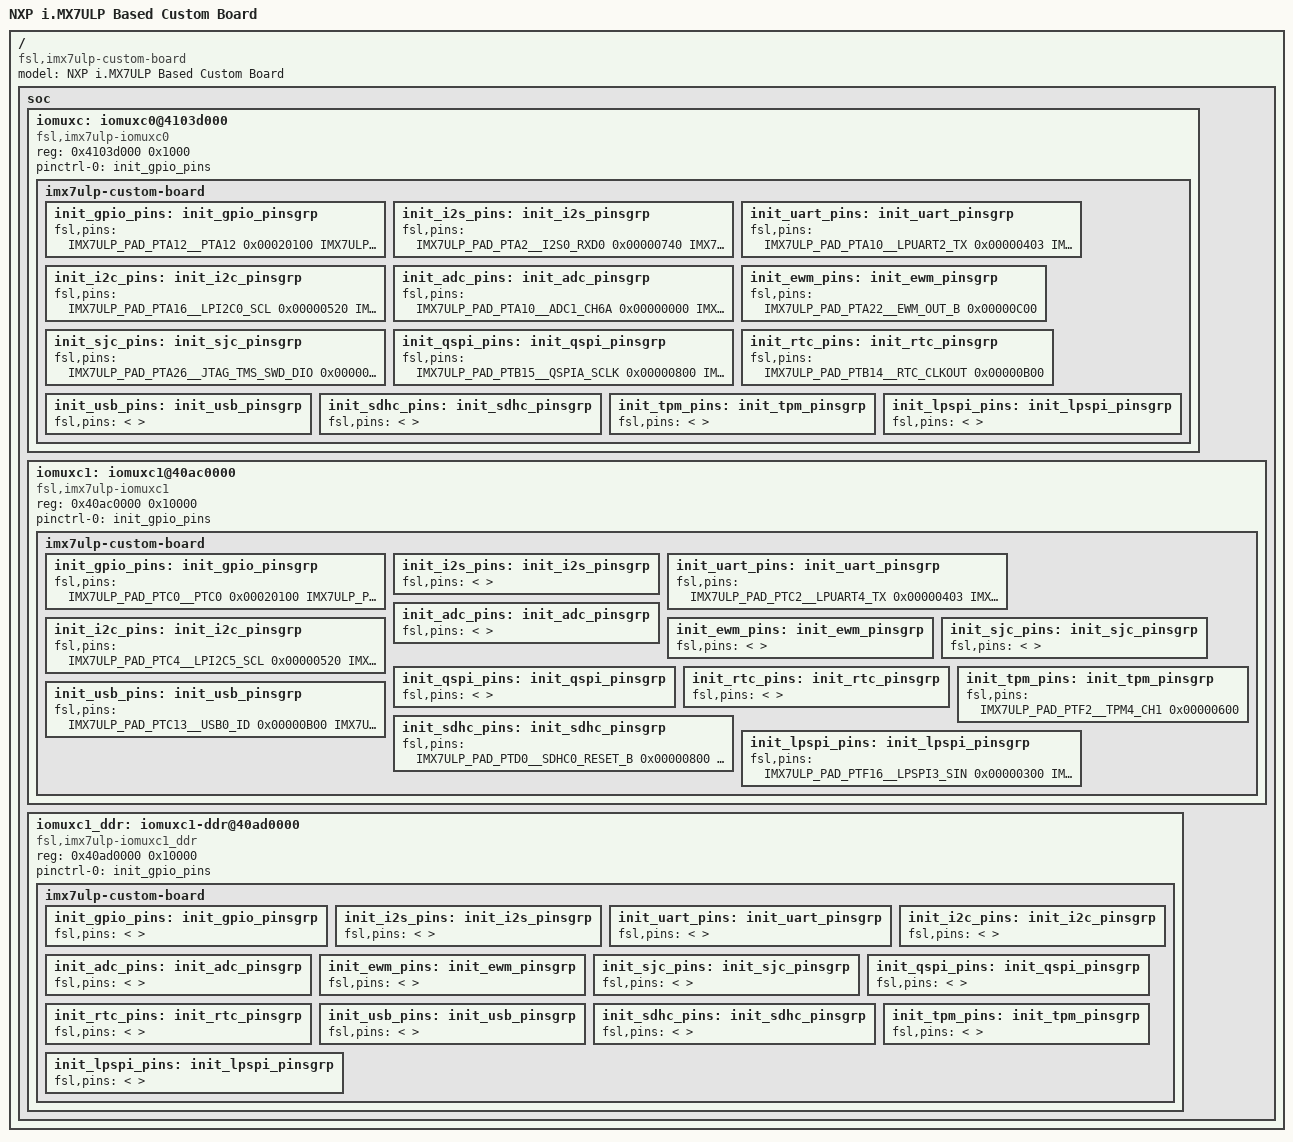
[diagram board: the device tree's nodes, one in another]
/***********************************************************************************************************************
 * This file was generated by the MCUXpresso Config Tools. Any manual edits made to this file
 * will be overwritten if the respective MCUXpresso Config Tools is used to update this file.
 **********************************************************************************************************************/

/*
 * TEXT BELOW IS USED AS SETTING FOR TOOLS *************************************
!!GlobalInfo
product: Pins v7.0
processor: MCIMX7U5xxxxx
package_id: MCIMX7U5CVP05
mcu_data: ksdk2_0
processor_version: 7.0.1
board: MCIMX7ULP-EVK-REV-B
 * BE CAREFUL MODIFYING THIS COMMENT - IT IS YAML SETTINGS FOR TOOLS ***********
 */


/dts-v1/;

#include "skeleton.dtsi"
#include "imx7ulp-pinfunc.h"

/ {
    model = "NXP i.MX7ULP Based Custom Board";
    compatible = "fsl,imx7ulp-custom-board", "fsl,imx7ulp";

    soc {
        #address-cells = <1>;
        #size-cells = <1>;

        iomuxc: iomuxc0@4103d000 {
            compatible = "fsl,imx7ulp-iomuxc0";
            reg = <0x4103d000 0x1000>;
        };
        iomuxc1: iomuxc1@40ac0000 {
            compatible = "fsl,imx7ulp-iomuxc1";
            reg = <0x40ac0000 0x10000>;
        };

        iomuxc1_ddr: iomuxc1-ddr@40ad0000 {
            compatible = "fsl,imx7ulp-iomuxc1_ddr";
            reg = <0x40ad0000 0x10000>;
        };
    };
};

&iomuxc {
    pinctrl-names = "default_iomuxc0";
    pinctrl-0 = <&init_gpio_pins>;


    imx7ulp-custom-board {
        init_gpio_pins: init_gpio_pinsgrp {                /*!< Function assigned for the core: Cortex-M4[cm4] */
/*
 * TEXT BELOW IS USED AS SETTING FOR TOOLS *************************************
init_gpio_pins:
- options: {callFromInitBoot: 'false', coreID: cm4}
- pin_list:
  - {pin_num: AG16, peripheral: PTA, signal: 'port, 12', pin_signal: PTA12, direction: OUTPUT, OBE: OBE_1_Enabled}
  - {pin_num: AF16, peripheral: PTA, signal: 'port, 13', pin_signal: PTA13, direction: INPUT, IBE: IBE_1_Enabled}
  - {pin_num: AF17, peripheral: PTA, signal: 'port, 14', pin_signal: PTA14, direction: OUTPUT, OBE: OBE_1_Enabled}
  - {pin_num: AF18, peripheral: PTA, signal: 'port, 15', pin_signal: PTA15, direction: OUTPUT, OBE: OBE_1_Enabled}
  - {pin_num: AB20, peripheral: PTA, signal: 'port, 21', pin_signal: PTA21, direction: OUTPUT, OBE: OBE_1_Enabled}
  - {pin_num: AD20, peripheral: PTA, signal: 'port, 23', pin_signal: PTA23, direction: INPUT, IBE: IBE_1_Enabled}
  - {pin_num: AF20, peripheral: PTA, signal: 'port, 24', pin_signal: PTA24, direction: OUTPUT, OBE: OBE_1_Enabled}
  - {pin_num: AG20, peripheral: PTA, signal: 'port, 25', pin_signal: PTA25, direction: OUTPUT, OBE: OBE_1_Enabled}
  - {pin_num: AF14, peripheral: PTA, signal: 'port, 3', pin_signal: PTA3, direction: OUTPUT, OBE: OBE_1_Enabled}
  - {pin_num: AF24, peripheral: PTA, signal: 'port, 31', pin_signal: PTA31, direction: INPUT, IBE: IBE_1_Enabled}
  - {pin_num: AF5, peripheral: PTB, signal: 'port, 6', pin_signal: PTB6, direction: OUTPUT, OBE: OBE_1_Enabled}
  - {pin_num: AF6, peripheral: PTB, signal: 'port, 7', pin_signal: PTB7, direction: INPUT, IBE: IBE_1_Enabled}
  - {pin_num: AD7, peripheral: PTB, signal: 'port, 9', pin_signal: PTB9, direction: INPUT, IBE: IBE_1_Enabled}
  - {pin_num: AB7, peripheral: PTB, signal: 'port, 11', pin_signal: PTB11, direction: INPUT, IBE: IBE_1_Enabled}
  - {pin_num: D18, peripheral: PTC, signal: 'port, 0', pin_signal: PTC0, direction: OUTPUT, OBE: OBE_1_Enabled}
  - {pin_num: B15, peripheral: PTC, signal: 'port, 10', pin_signal: PTC10, direction: INPUT, IBE: IBE_1_Enabled, PE: PE_1_pull_enabled, PS: PS_1_pull_up}
  - {pin_num: B14, peripheral: PTC, signal: 'port, 11', pin_signal: PTC11, direction: INPUT, IBE: IBE_1_Enabled}
  - {pin_num: A14, peripheral: PTC, signal: 'port, 12', pin_signal: PTC12, direction: INPUT, IBE: IBE_1_Enabled}
  - {pin_num: E13, peripheral: PTC, signal: 'port, 14', pin_signal: PTC14, direction: OUTPUT, OBE: OBE_1_Enabled}
  - {pin_num: F13, peripheral: PTC, signal: 'port, 15', pin_signal: PTC15, direction: OUTPUT, OBE: OBE_1_Enabled}
  - {pin_num: G12, peripheral: PTC, signal: 'port, 17', pin_signal: PTC17, direction: OUTPUT, OBE: OBE_1_Enabled}
  - {pin_num: F12, peripheral: PTC, signal: 'port, 18', pin_signal: PTC18, direction: INPUT, IBE: IBE_1_Enabled, PE: PE_1_pull_enabled, PS: PS_1_pull_up}
  - {pin_num: E12, peripheral: PTC, signal: 'port, 19', pin_signal: PTC19, direction: OUTPUT, OBE: OBE_1_Enabled, PE: PE_1_pull_enabled, PS: PS_1_pull_up}
  - {pin_num: B8, peripheral: PTE, signal: 'port, 12', pin_signal: PTE12, direction: OUTPUT, OBE: OBE_1_Enabled}
  - {pin_num: D2, peripheral: PTF, signal: 'port, 0', pin_signal: PTF0, direction: INPUT, IBE: IBE_1_Enabled}
  - {pin_num: B2, peripheral: PTF, signal: 'port, 1', pin_signal: PTF1, direction: OUTPUT, OBE: OBE_1_Enabled}
  - {pin_num: G5, peripheral: PTF, signal: 'port, 10', pin_signal: PTF10, direction: OUTPUT, OBE: OBE_1_Enabled}
  - {pin_num: G6, peripheral: PTF, signal: 'port, 11', pin_signal: PTF11, direction: OUTPUT, OBE: OBE_1_Enabled}
 * BE CAREFUL MODIFYING THIS COMMENT - IT IS YAML SETTINGS FOR TOOLS ***********
 */
            fsl,pins = <
                IMX7ULP_PAD_PTA12__PTA12                   0x00020100
                IMX7ULP_PAD_PTA13__PTA13                   0x00010100
                IMX7ULP_PAD_PTA14__PTA14                   0x00020100
                IMX7ULP_PAD_PTA15__PTA15                   0x00020100
                IMX7ULP_PAD_PTA21__PTA21                   0x00020100
                IMX7ULP_PAD_PTA23__PTA23                   0x00010100
                IMX7ULP_PAD_PTA24__PTA24                   0x00020100
                IMX7ULP_PAD_PTA25__PTA25                   0x00020100
                IMX7ULP_PAD_PTA3__PTA3                     0x00020100
                IMX7ULP_PAD_PTA31__PTA31                   0x00010100
                IMX7ULP_PAD_PTB11__PTB11                   0x00010100
                IMX7ULP_PAD_PTB6__PTB6                     0x00020100
                IMX7ULP_PAD_PTB7__PTB7                     0x00010100
                IMX7ULP_PAD_PTB9__PTB9                     0x00010100
            >;
        };
        init_i2s_pins: init_i2s_pinsgrp {                  /*!< Function assigned for the core: Cortex-M4[cm4] */
/*
 * TEXT BELOW IS USED AS SETTING FOR TOOLS *************************************
init_i2s_pins:
- options: {callFromInitBoot: 'false', coreID: cm4}
- pin_list:
  - {pin_num: AG14, peripheral: I2S0, signal: 'i2s_rxd, 0', pin_signal: PTA2, DSE: DSE_1_Hi_Drive}
  - {pin_num: AD15, peripheral: I2S0, signal: i2s_mclk, pin_signal: PTA4, DSE: DSE_1_Hi_Drive}
  - {pin_num: AC15, peripheral: I2S0, signal: i2s_tx_bclk, pin_signal: PTA5, DSE: DSE_1_Hi_Drive}
  - {pin_num: AB15, peripheral: I2S0, signal: i2s_tx_fs, pin_signal: PTA6, DSE: DSE_1_Hi_Drive}
  - {pin_num: AD14, peripheral: I2S0, signal: 'i2s_txd, 0', pin_signal: PTA7, DSE: DSE_1_Hi_Drive}
  - {pin_num: AF2, peripheral: I2S1, signal: i2s_tx_bclk, pin_signal: PTB1, DSE: DSE_1_Hi_Drive}
  - {pin_num: AE3, peripheral: I2S1, signal: i2s_tx_fs, pin_signal: PTB2, DSE: DSE_1_Hi_Drive}
  - {pin_num: AE4, peripheral: I2S1, signal: 'i2s_txd, 0', pin_signal: PTB3, DSE: DSE_1_Hi_Drive}
  - {pin_num: AC7, peripheral: I2S1, signal: 'i2s_rxd, 0', pin_signal: PTB10, DSE: DSE_1_Hi_Drive}
 * BE CAREFUL MODIFYING THIS COMMENT - IT IS YAML SETTINGS FOR TOOLS ***********
 */
            fsl,pins = <
                IMX7ULP_PAD_PTA2__I2S0_RXD0                0x00000740
                IMX7ULP_PAD_PTA4__I2S0_MCLK                0x00000740
                IMX7ULP_PAD_PTA5__I2S0_TX_BCLK             0x00000740
                IMX7ULP_PAD_PTA6__I2S0_TX_FS               0x00000740
                IMX7ULP_PAD_PTA7__I2S0_TXD0                0x00000740
                IMX7ULP_PAD_PTB1__I2S1_TX_BCLK             0x00000740
                IMX7ULP_PAD_PTB10__I2S1_RXD0               0x00000740
                IMX7ULP_PAD_PTB2__I2S1_TX_FS               0x00000740
                IMX7ULP_PAD_PTB3__I2S1_TXD0                0x00000740
            >;
        };
        init_uart_pins: init_uart_pinsgrp {                /*!< Function assigned for the core: Cortex-M4[cm4] */
/*
 * TEXT BELOW IS USED AS SETTING FOR TOOLS *************************************
init_uart_pins:
- options: {callFromInitBoot: 'false', coreID: cm4}
- pin_list:
  - {pin_num: AB16, peripheral: LPUART2, signal: lpuart_cts_b, pin_signal: PTA8, identifier: UART2_CTS, PE: PE_1_pull_enabled, PS: PS_1_pull_up}
  - {pin_num: AC16, peripheral: LPUART2, signal: lpuart_rts_b, pin_signal: PTA9, identifier: UART2_RTS, PE: PE_1_pull_enabled, PS: PS_1_pull_up}
  - {pin_num: AD16, peripheral: LPUART2, signal: lpuart_tx, pin_signal: PTA10, identifier: UART2_TX, PE: PE_1_pull_enabled, PS: PS_1_pull_up}
  - {pin_num: AD18, peripheral: LPUART2, signal: lpuart_rx, pin_signal: PTA11, identifier: UART2_RX, PE: PE_1_pull_enabled, PS: PS_1_pull_up}
  - {pin_num: AC19, peripheral: LPUART0, signal: lpuart_tx, pin_signal: PTA18, PE: PE_1_pull_enabled, PS: PS_1_pull_up}
  - {pin_num: AB19, peripheral: LPUART0, signal: lpuart_rx, pin_signal: PTA19, PE: PE_1_pull_enabled, PS: PS_1_pull_up}
  - {pin_num: F17, peripheral: LPUART4, signal: lpuart_tx, pin_signal: PTC2, PE: PE_1_pull_enabled, PS: PS_1_pull_up}
  - {pin_num: G17, peripheral: LPUART4, signal: lpuart_rx, pin_signal: PTC3, PE: PE_1_pull_enabled, PS: PS_1_pull_up}
  - {pin_num: F9, peripheral: LPUART6, signal: lpuart_cts_b, pin_signal: PTE8, PE: PE_1_pull_enabled, PS: PS_1_pull_up}
  - {pin_num: G9, peripheral: LPUART6, signal: lpuart_rts_b, pin_signal: PTE9, PE: PE_1_pull_enabled, PS: PS_1_pull_up}
  - {pin_num: D8, peripheral: LPUART6, signal: lpuart_tx, pin_signal: PTE10, PE: PE_1_pull_enabled, PS: PS_1_pull_up}
  - {pin_num: A8, peripheral: LPUART6, signal: lpuart_rx, pin_signal: PTE11, PE: PE_1_pull_enabled, PS: PS_1_pull_up}
 * BE CAREFUL MODIFYING THIS COMMENT - IT IS YAML SETTINGS FOR TOOLS ***********
 */
            fsl,pins = <
                IMX7ULP_PAD_PTA10__LPUART2_TX              0x00000403
                IMX7ULP_PAD_PTA11__LPUART2_RX              0x00000403
                IMX7ULP_PAD_PTA18__LPUART0_TX              0x00000403
                IMX7ULP_PAD_PTA19__LPUART0_RX              0x00000403
                IMX7ULP_PAD_PTA8__LPUART2_CTS_B            0x00000403
                IMX7ULP_PAD_PTA9__LPUART2_RTS_B            0x00000403
            >;
        };
        init_i2c_pins: init_i2c_pinsgrp {                  /*!< Function assigned for the core: Cortex-M4[cm4] */
/*
 * TEXT BELOW IS USED AS SETTING FOR TOOLS *************************************
init_i2c_pins:
- options: {callFromInitBoot: 'false', coreID: cm4}
- pin_list:
  - {pin_num: AG18, peripheral: LPI2C0, signal: lpi2c_scl, pin_signal: PTA16, ODE: ODE_1_Open_drain}
  - {pin_num: AD19, peripheral: LPI2C0, signal: lpi2c_sda, pin_signal: PTA17, ODE: ODE_1_Open_drain}
  - {pin_num: AC8, peripheral: LPI2C3, signal: lpi2c_scl, pin_signal: PTB12, ODE: ODE_1_Open_drain}
  - {pin_num: AD8, peripheral: LPI2C3, signal: lpi2c_sda, pin_signal: PTB13, ODE: ODE_1_Open_drain}
  - {pin_num: F16, peripheral: LPI2C5, signal: lpi2c_scl, pin_signal: PTC4, ODE: ODE_1_Open_drain}
  - {pin_num: D17, peripheral: LPI2C5, signal: lpi2c_sda, pin_signal: PTC5, ODE: ODE_1_Open_drain}
  - {pin_num: H7, peripheral: LPI2C7, signal: lpi2c_scl, pin_signal: PTF12, ODE: ODE_1_Open_drain}
  - {pin_num: H6, peripheral: LPI2C7, signal: lpi2c_sda, pin_signal: PTF13, ODE: ODE_1_Open_drain}
 * BE CAREFUL MODIFYING THIS COMMENT - IT IS YAML SETTINGS FOR TOOLS ***********
 */
            fsl,pins = <
                IMX7ULP_PAD_PTA16__LPI2C0_SCL              0x00000520
                IMX7ULP_PAD_PTA17__LPI2C0_SDA              0x00000520
                IMX7ULP_PAD_PTB12__LPI2C3_SCL              0x00000520
                IMX7ULP_PAD_PTB13__LPI2C3_SDA              0x00000520
            >;
        };
        init_adc_pins: init_adc_pinsgrp {                  /*!< Function assigned for the core: Cortex-M4[cm4] */
/*
 * TEXT BELOW IS USED AS SETTING FOR TOOLS *************************************
init_adc_pins:
- options: {callFromInitBoot: 'false', coreID: cm4}
- pin_list:
  - {pin_num: AD22, peripheral: ADC0, signal: adc_ch10a, pin_signal: PTA20}
  - {pin_num: AB16, peripheral: ADC1, signal: adc_ch5a, pin_signal: PTA8, identifier: ADC1_CH5A}
  - {pin_num: AC16, peripheral: ADC1, signal: adc_ch5b, pin_signal: PTA9, identifier: ADC1_CH5B}
  - {pin_num: AD16, peripheral: ADC1, signal: adc_ch6a, pin_signal: PTA10, identifier: ADC1_CH6A}
  - {pin_num: AD18, peripheral: ADC1, signal: adc_ch6b, pin_signal: PTA11, identifier: ADC1_CH6B}
 * BE CAREFUL MODIFYING THIS COMMENT - IT IS YAML SETTINGS FOR TOOLS ***********
 */
            fsl,pins = <
                IMX7ULP_PAD_PTA10__ADC1_CH6A               0x00000000
                IMX7ULP_PAD_PTA11__ADC1_CH6B               0x00000000
                IMX7ULP_PAD_PTA20__ADC0_CH10A              0x00000000
                IMX7ULP_PAD_PTA8__ADC1_CH5A                0x00000000
                IMX7ULP_PAD_PTA9__ADC1_CH5B                0x00000000
            >;
        };
        init_ewm_pins: init_ewm_pinsgrp {                  /*!< Function assigned for the core: Cortex-M4[cm4] */
/*
 * TEXT BELOW IS USED AS SETTING FOR TOOLS *************************************
init_ewm_pins:
- options: {callFromInitBoot: 'false', coreID: cm4}
- pin_list:
  - {pin_num: AC20, peripheral: EWM, signal: ewm_out_b, pin_signal: PTA22}
 * BE CAREFUL MODIFYING THIS COMMENT - IT IS YAML SETTINGS FOR TOOLS ***********
 */
            fsl,pins = <
                IMX7ULP_PAD_PTA22__EWM_OUT_B               0x00000C00
            >;
        };
        init_sjc_pins: init_sjc_pinsgrp {                  /*!< Function assigned for the core: Cortex-M4[cm4] */
/*
 * TEXT BELOW IS USED AS SETTING FOR TOOLS *************************************
init_sjc_pins:
- options: {callFromInitBoot: 'false', coreID: cm4}
- pin_list:
  - {pin_num: AF21, peripheral: JTAG, signal: jtag_tms, pin_signal: PTA26, identifier: JTAG_TMS}
  - {pin_num: AF22, peripheral: JTAG, signal: jtag_tdo, pin_signal: PTA27}
  - {pin_num: AG22, peripheral: JTAG, signal: jtag_tdi, pin_signal: PTA28}
  - {pin_num: AD23, peripheral: JTAG, signal: jtag_tclk, pin_signal: PTA29, identifier: JTAG_TCLK}
  - {pin_num: AD24, peripheral: JTAG, signal: jtag_trst_b, pin_signal: PTA30}
 * BE CAREFUL MODIFYING THIS COMMENT - IT IS YAML SETTINGS FOR TOOLS ***********
 */
            fsl,pins = <
                IMX7ULP_PAD_PTA26__JTAG_TMS_SWD_DIO        0x00000A03
                IMX7ULP_PAD_PTA27__JTAG_TDO                0x00000A00
                IMX7ULP_PAD_PTA28__JTAG_TDI                0x00000A03
                IMX7ULP_PAD_PTA29__JTAG_TCLK_SWD_CLK       0x00000A02
                IMX7ULP_PAD_PTA30__JTAG_TRST_B             0x00000A03
            >;
        };
        init_qspi_pins: init_qspi_pinsgrp {                /*!< Function assigned for the core: Cortex-M4[cm4] */
/*
 * TEXT BELOW IS USED AS SETTING FOR TOOLS *************************************
init_qspi_pins:
- options: {callFromInitBoot: 'false', coreID: cm4}
- pin_list:
  - {pin_num: AG6, peripheral: QSPIA, signal: 'qspia_ss_b, 0', pin_signal: PTB8}
  - {pin_num: AF8, peripheral: QSPIA, signal: qspia_sclk, pin_signal: PTB15}
  - {pin_num: AF9, peripheral: QSPIA, signal: 'qspia_data, 3', pin_signal: PTB16}
  - {pin_num: AF10, peripheral: QSPIA, signal: 'qspia_data, 2', pin_signal: PTB17}
  - {pin_num: AG10, peripheral: QSPIA, signal: 'qspia_data, 1', pin_signal: PTB18}
  - {pin_num: AD10, peripheral: QSPIA, signal: 'qspia_data, 0', pin_signal: PTB19}
 * BE CAREFUL MODIFYING THIS COMMENT - IT IS YAML SETTINGS FOR TOOLS ***********
 */
            fsl,pins = <
                IMX7ULP_PAD_PTB15__QSPIA_SCLK              0x00000800
                IMX7ULP_PAD_PTB16__QSPIA_DATA3             0x00000800
                IMX7ULP_PAD_PTB17__QSPIA_DATA2             0x00000800
                IMX7ULP_PAD_PTB18__QSPIA_DATA1             0x00000800
                IMX7ULP_PAD_PTB19__QSPIA_DATA0             0x00000800
                IMX7ULP_PAD_PTB8__QSPIA_SS0_B              0x00000800
            >;
        };
        init_rtc_pins: init_rtc_pinsgrp {                  /*!< Function assigned for the core: Cortex-M4[cm4] */
/*
 * TEXT BELOW IS USED AS SETTING FOR TOOLS *************************************
init_rtc_pins:
- options: {callFromInitBoot: 'false', coreID: cm4}
- pin_list:
  - {pin_num: AG8, peripheral: RTC, signal: rtc_clkout, pin_signal: PTB14}
 * BE CAREFUL MODIFYING THIS COMMENT - IT IS YAML SETTINGS FOR TOOLS ***********
 */
            fsl,pins = <
                IMX7ULP_PAD_PTB14__RTC_CLKOUT              0x00000B00
            >;
        };
        init_usb_pins: init_usb_pinsgrp {                  /*!< Function assigned for the core: Cortex-M4[cm4] */
/*
 * TEXT BELOW IS USED AS SETTING FOR TOOLS *************************************
init_usb_pins:
- options: {callFromInitBoot: 'false', coreID: cm4}
- pin_list:
  - {pin_num: D13, peripheral: USB0, signal: usb0_id, pin_signal: PTC13}
  - {pin_num: G13, peripheral: USB1, signal: 'usb1_oc, 2', pin_signal: PTC16}
 * BE CAREFUL MODIFYING THIS COMMENT - IT IS YAML SETTINGS FOR TOOLS ***********
 */
            fsl,pins = <
            >;
        };
        init_sdhc_pins: init_sdhc_pinsgrp {                /*!< Function assigned for the core: Cortex-M4[cm4] */
/*
 * TEXT BELOW IS USED AS SETTING FOR TOOLS *************************************
init_sdhc_pins:
- options: {callFromInitBoot: 'false', coreID: cm4}
- pin_list:
  - {pin_num: A24, peripheral: SDHC0, signal: sdhc_reset_b, pin_signal: PTD0}
  - {pin_num: B24, peripheral: SDHC0, signal: sdhc_cmd, pin_signal: PTD1}
  - {pin_num: B23, peripheral: SDHC0, signal: sdhc_clk, pin_signal: PTD2, IBE: IBE_1_Enabled}
  - {pin_num: B22, peripheral: SDHC0, signal: 'sdhc_d, 7', pin_signal: PTD3}
  - {pin_num: A22, peripheral: SDHC0, signal: 'sdhc_d, 6', pin_signal: PTD4}
  - {pin_num: D21, peripheral: SDHC0, signal: 'sdhc_d, 5', pin_signal: PTD5}
  - {pin_num: D22, peripheral: SDHC0, signal: 'sdhc_d, 4', pin_signal: PTD6}
  - {pin_num: A20, peripheral: SDHC0, signal: 'sdhc_d, 3', pin_signal: PTD7}
  - {pin_num: B20, peripheral: SDHC0, signal: 'sdhc_d, 2', pin_signal: PTD8}
  - {pin_num: B19, peripheral: SDHC0, signal: 'sdhc_d, 1', pin_signal: PTD9}
  - {pin_num: B18, peripheral: SDHC0, signal: 'sdhc_d, 0', pin_signal: PTD10}
  - {pin_num: A18, peripheral: SDHC0, signal: sdhc_dqs, pin_signal: PTD11}
  - {pin_num: D12, peripheral: SDHC1, signal: 'sdhc_d, 1', pin_signal: PTE0}
  - {pin_num: A12, peripheral: SDHC1, signal: 'sdhc_d, 0', pin_signal: PTE1}
  - {pin_num: B12, peripheral: SDHC1, signal: sdhc_clk, pin_signal: PTE2, IBE: IBE_1_Enabled}
  - {pin_num: B11, peripheral: SDHC1, signal: sdhc_cmd, pin_signal: PTE3}
  - {pin_num: B10, peripheral: SDHC1, signal: 'sdhc_d, 3', pin_signal: PTE4}
  - {pin_num: A10, peripheral: SDHC1, signal: 'sdhc_d, 2', pin_signal: PTE5}
  - {pin_num: B6, peripheral: SDHC1, signal: sdhc_vs, pin_signal: PTE14}
 * BE CAREFUL MODIFYING THIS COMMENT - IT IS YAML SETTINGS FOR TOOLS ***********
 */
            fsl,pins = <
            >;
        };
        init_tpm_pins: init_tpm_pinsgrp {                  /*!< Function assigned for the core: Cortex-M4[cm4] */
/*
 * TEXT BELOW IS USED AS SETTING FOR TOOLS *************************************
init_tpm_pins:
- options: {callFromInitBoot: 'false', coreID: cm4}
- pin_list:
  - {pin_num: B3, peripheral: TPM4, signal: 'tpm_ch, 1', pin_signal: PTF2}
 * BE CAREFUL MODIFYING THIS COMMENT - IT IS YAML SETTINGS FOR TOOLS ***********
 */
            fsl,pins = <
            >;
        };
        init_lpspi_pins: init_lpspi_pinsgrp {              /*!< Function assigned for the core: Cortex-A7[ca7] */
/*
 * TEXT BELOW IS USED AS SETTING FOR TOOLS *************************************
init_lpspi_pins:
- options: {callFromInitBoot: 'true', coreID: ca7}
- pin_list:
  - {pin_num: H2, peripheral: LPSPI3, signal: lpspi_sout, pin_signal: PTF17}
  - {pin_num: J2, peripheral: LPSPI3, signal: lpspi_sck, pin_signal: PTF18}
  - {pin_num: K2, peripheral: LPSPI3, signal: 'lpspi_pcs, 0', pin_signal: PTF19}
  - {pin_num: H1, peripheral: LPSPI3, signal: lpspi_sin, pin_signal: PTF16}
 * BE CAREFUL MODIFYING THIS COMMENT - IT IS YAML SETTINGS FOR TOOLS ***********
 */
            fsl,pins = <
            >;
        };
    };
};

&iomuxc1 {
    pinctrl-names = "default_iomuxc1";
    pinctrl-0 = <&init_gpio_pins>;


    imx7ulp-custom-board {
        init_gpio_pins: init_gpio_pinsgrp {                /*!< Function assigned for the core: Cortex-M4[cm4] */
/*
 * TEXT BELOW IS USED AS SETTING FOR TOOLS *************************************
init_gpio_pins:
- options: {callFromInitBoot: 'false', coreID: cm4}
- pin_list:
  - {pin_num: AG16, peripheral: PTA, signal: 'port, 12', pin_signal: PTA12, direction: OUTPUT, OBE: OBE_1_Enabled}
  - {pin_num: AF16, peripheral: PTA, signal: 'port, 13', pin_signal: PTA13, direction: INPUT, IBE: IBE_1_Enabled}
  - {pin_num: AF17, peripheral: PTA, signal: 'port, 14', pin_signal: PTA14, direction: OUTPUT, OBE: OBE_1_Enabled}
  - {pin_num: AF18, peripheral: PTA, signal: 'port, 15', pin_signal: PTA15, direction: OUTPUT, OBE: OBE_1_Enabled}
  - {pin_num: AB20, peripheral: PTA, signal: 'port, 21', pin_signal: PTA21, direction: OUTPUT, OBE: OBE_1_Enabled}
  - {pin_num: AD20, peripheral: PTA, signal: 'port, 23', pin_signal: PTA23, direction: INPUT, IBE: IBE_1_Enabled}
  - {pin_num: AF20, peripheral: PTA, signal: 'port, 24', pin_signal: PTA24, direction: OUTPUT, OBE: OBE_1_Enabled}
  - {pin_num: AG20, peripheral: PTA, signal: 'port, 25', pin_signal: PTA25, direction: OUTPUT, OBE: OBE_1_Enabled}
  - {pin_num: AF14, peripheral: PTA, signal: 'port, 3', pin_signal: PTA3, direction: OUTPUT, OBE: OBE_1_Enabled}
  - {pin_num: AF24, peripheral: PTA, signal: 'port, 31', pin_signal: PTA31, direction: INPUT, IBE: IBE_1_Enabled}
  - {pin_num: AF5, peripheral: PTB, signal: 'port, 6', pin_signal: PTB6, direction: OUTPUT, OBE: OBE_1_Enabled}
  - {pin_num: AF6, peripheral: PTB, signal: 'port, 7', pin_signal: PTB7, direction: INPUT, IBE: IBE_1_Enabled}
  - {pin_num: AD7, peripheral: PTB, signal: 'port, 9', pin_signal: PTB9, direction: INPUT, IBE: IBE_1_Enabled}
  - {pin_num: AB7, peripheral: PTB, signal: 'port, 11', pin_signal: PTB11, direction: INPUT, IBE: IBE_1_Enabled}
  - {pin_num: D18, peripheral: PTC, signal: 'port, 0', pin_signal: PTC0, direction: OUTPUT, OBE: OBE_1_Enabled}
  - {pin_num: B15, peripheral: PTC, signal: 'port, 10', pin_signal: PTC10, direction: INPUT, IBE: IBE_1_Enabled, PE: PE_1_pull_enabled, PS: PS_1_pull_up}
  - {pin_num: B14, peripheral: PTC, signal: 'port, 11', pin_signal: PTC11, direction: INPUT, IBE: IBE_1_Enabled}
  - {pin_num: A14, peripheral: PTC, signal: 'port, 12', pin_signal: PTC12, direction: INPUT, IBE: IBE_1_Enabled}
  - {pin_num: E13, peripheral: PTC, signal: 'port, 14', pin_signal: PTC14, direction: OUTPUT, OBE: OBE_1_Enabled}
  - {pin_num: F13, peripheral: PTC, signal: 'port, 15', pin_signal: PTC15, direction: OUTPUT, OBE: OBE_1_Enabled}
  - {pin_num: G12, peripheral: PTC, signal: 'port, 17', pin_signal: PTC17, direction: OUTPUT, OBE: OBE_1_Enabled}
  - {pin_num: F12, peripheral: PTC, signal: 'port, 18', pin_signal: PTC18, direction: INPUT, IBE: IBE_1_Enabled, PE: PE_1_pull_enabled, PS: PS_1_pull_up}
  - {pin_num: E12, peripheral: PTC, signal: 'port, 19', pin_signal: PTC19, direction: OUTPUT, OBE: OBE_1_Enabled, PE: PE_1_pull_enabled, PS: PS_1_pull_up}
  - {pin_num: B8, peripheral: PTE, signal: 'port, 12', pin_signal: PTE12, direction: OUTPUT, OBE: OBE_1_Enabled}
  - {pin_num: D2, peripheral: PTF, signal: 'port, 0', pin_signal: PTF0, direction: INPUT, IBE: IBE_1_Enabled}
  - {pin_num: B2, peripheral: PTF, signal: 'port, 1', pin_signal: PTF1, direction: OUTPUT, OBE: OBE_1_Enabled}
  - {pin_num: G5, peripheral: PTF, signal: 'port, 10', pin_signal: PTF10, direction: OUTPUT, OBE: OBE_1_Enabled}
  - {pin_num: G6, peripheral: PTF, signal: 'port, 11', pin_signal: PTF11, direction: OUTPUT, OBE: OBE_1_Enabled}
 * BE CAREFUL MODIFYING THIS COMMENT - IT IS YAML SETTINGS FOR TOOLS ***********
 */
            fsl,pins = <
                IMX7ULP_PAD_PTC0__PTC0                     0x00020100
                IMX7ULP_PAD_PTC10__PTC10                   0x00010103
                IMX7ULP_PAD_PTC11__PTC11                   0x00010100
                IMX7ULP_PAD_PTC12__PTC12                   0x00010100
                IMX7ULP_PAD_PTC14__PTC14                   0x00020100
                IMX7ULP_PAD_PTC15__PTC15                   0x00020100
                IMX7ULP_PAD_PTC17__PTC17                   0x00020100
                IMX7ULP_PAD_PTC18__PTC18                   0x00010103
                IMX7ULP_PAD_PTC19__PTC19                   0x00020103
                IMX7ULP_PAD_PTE12__PTE12                   0x00020100
                IMX7ULP_PAD_PTF0__PTF0                     0x00010100
                IMX7ULP_PAD_PTF1__PTF1                     0x00020100
                IMX7ULP_PAD_PTF10__PTF10                   0x00020100
                IMX7ULP_PAD_PTF11__PTF11                   0x00020100
            >;
        };
        init_i2s_pins: init_i2s_pinsgrp {                  /*!< Function assigned for the core: Cortex-M4[cm4] */
/*
 * TEXT BELOW IS USED AS SETTING FOR TOOLS *************************************
init_i2s_pins:
- options: {callFromInitBoot: 'false', coreID: cm4}
- pin_list:
  - {pin_num: AG14, peripheral: I2S0, signal: 'i2s_rxd, 0', pin_signal: PTA2, DSE: DSE_1_Hi_Drive}
  - {pin_num: AD15, peripheral: I2S0, signal: i2s_mclk, pin_signal: PTA4, DSE: DSE_1_Hi_Drive}
  - {pin_num: AC15, peripheral: I2S0, signal: i2s_tx_bclk, pin_signal: PTA5, DSE: DSE_1_Hi_Drive}
  - {pin_num: AB15, peripheral: I2S0, signal: i2s_tx_fs, pin_signal: PTA6, DSE: DSE_1_Hi_Drive}
  - {pin_num: AD14, peripheral: I2S0, signal: 'i2s_txd, 0', pin_signal: PTA7, DSE: DSE_1_Hi_Drive}
  - {pin_num: AF2, peripheral: I2S1, signal: i2s_tx_bclk, pin_signal: PTB1, DSE: DSE_1_Hi_Drive}
  - {pin_num: AE3, peripheral: I2S1, signal: i2s_tx_fs, pin_signal: PTB2, DSE: DSE_1_Hi_Drive}
  - {pin_num: AE4, peripheral: I2S1, signal: 'i2s_txd, 0', pin_signal: PTB3, DSE: DSE_1_Hi_Drive}
  - {pin_num: AC7, peripheral: I2S1, signal: 'i2s_rxd, 0', pin_signal: PTB10, DSE: DSE_1_Hi_Drive}
 * BE CAREFUL MODIFYING THIS COMMENT - IT IS YAML SETTINGS FOR TOOLS ***********
 */
            fsl,pins = <
            >;
        };
        init_uart_pins: init_uart_pinsgrp {                /*!< Function assigned for the core: Cortex-M4[cm4] */
/*
 * TEXT BELOW IS USED AS SETTING FOR TOOLS *************************************
init_uart_pins:
- options: {callFromInitBoot: 'false', coreID: cm4}
- pin_list:
  - {pin_num: AB16, peripheral: LPUART2, signal: lpuart_cts_b, pin_signal: PTA8, identifier: UART2_CTS, PE: PE_1_pull_enabled, PS: PS_1_pull_up}
  - {pin_num: AC16, peripheral: LPUART2, signal: lpuart_rts_b, pin_signal: PTA9, identifier: UART2_RTS, PE: PE_1_pull_enabled, PS: PS_1_pull_up}
  - {pin_num: AD16, peripheral: LPUART2, signal: lpuart_tx, pin_signal: PTA10, identifier: UART2_TX, PE: PE_1_pull_enabled, PS: PS_1_pull_up}
  - {pin_num: AD18, peripheral: LPUART2, signal: lpuart_rx, pin_signal: PTA11, identifier: UART2_RX, PE: PE_1_pull_enabled, PS: PS_1_pull_up}
  - {pin_num: AC19, peripheral: LPUART0, signal: lpuart_tx, pin_signal: PTA18, PE: PE_1_pull_enabled, PS: PS_1_pull_up}
  - {pin_num: AB19, peripheral: LPUART0, signal: lpuart_rx, pin_signal: PTA19, PE: PE_1_pull_enabled, PS: PS_1_pull_up}
  - {pin_num: F17, peripheral: LPUART4, signal: lpuart_tx, pin_signal: PTC2, PE: PE_1_pull_enabled, PS: PS_1_pull_up}
  - {pin_num: G17, peripheral: LPUART4, signal: lpuart_rx, pin_signal: PTC3, PE: PE_1_pull_enabled, PS: PS_1_pull_up}
  - {pin_num: F9, peripheral: LPUART6, signal: lpuart_cts_b, pin_signal: PTE8, PE: PE_1_pull_enabled, PS: PS_1_pull_up}
  - {pin_num: G9, peripheral: LPUART6, signal: lpuart_rts_b, pin_signal: PTE9, PE: PE_1_pull_enabled, PS: PS_1_pull_up}
  - {pin_num: D8, peripheral: LPUART6, signal: lpuart_tx, pin_signal: PTE10, PE: PE_1_pull_enabled, PS: PS_1_pull_up}
  - {pin_num: A8, peripheral: LPUART6, signal: lpuart_rx, pin_signal: PTE11, PE: PE_1_pull_enabled, PS: PS_1_pull_up}
 * BE CAREFUL MODIFYING THIS COMMENT - IT IS YAML SETTINGS FOR TOOLS ***********
 */
            fsl,pins = <
                IMX7ULP_PAD_PTC2__LPUART4_TX               0x00000403
                IMX7ULP_PAD_PTC3__LPUART4_RX               0x00000403
                IMX7ULP_PAD_PTE10__LPUART6_TX              0x00000403
                IMX7ULP_PAD_PTE11__LPUART6_RX              0x00000403
                IMX7ULP_PAD_PTE8__LPUART6_CTS_B            0x00000403
                IMX7ULP_PAD_PTE9__LPUART6_RTS_B            0x00000403
            >;
        };
        init_i2c_pins: init_i2c_pinsgrp {                  /*!< Function assigned for the core: Cortex-M4[cm4] */
/*
 * TEXT BELOW IS USED AS SETTING FOR TOOLS *************************************
init_i2c_pins:
- options: {callFromInitBoot: 'false', coreID: cm4}
- pin_list:
  - {pin_num: AG18, peripheral: LPI2C0, signal: lpi2c_scl, pin_signal: PTA16, ODE: ODE_1_Open_drain}
  - {pin_num: AD19, peripheral: LPI2C0, signal: lpi2c_sda, pin_signal: PTA17, ODE: ODE_1_Open_drain}
  - {pin_num: AC8, peripheral: LPI2C3, signal: lpi2c_scl, pin_signal: PTB12, ODE: ODE_1_Open_drain}
  - {pin_num: AD8, peripheral: LPI2C3, signal: lpi2c_sda, pin_signal: PTB13, ODE: ODE_1_Open_drain}
  - {pin_num: F16, peripheral: LPI2C5, signal: lpi2c_scl, pin_signal: PTC4, ODE: ODE_1_Open_drain}
  - {pin_num: D17, peripheral: LPI2C5, signal: lpi2c_sda, pin_signal: PTC5, ODE: ODE_1_Open_drain}
  - {pin_num: H7, peripheral: LPI2C7, signal: lpi2c_scl, pin_signal: PTF12, ODE: ODE_1_Open_drain}
  - {pin_num: H6, peripheral: LPI2C7, signal: lpi2c_sda, pin_signal: PTF13, ODE: ODE_1_Open_drain}
 * BE CAREFUL MODIFYING THIS COMMENT - IT IS YAML SETTINGS FOR TOOLS ***********
 */
            fsl,pins = <
                IMX7ULP_PAD_PTC4__LPI2C5_SCL               0x00000520
                IMX7ULP_PAD_PTC5__LPI2C5_SDA               0x00000520
                IMX7ULP_PAD_PTF12__LPI2C7_SCL              0x00000520
                IMX7ULP_PAD_PTF13__LPI2C7_SDA              0x00000520
            >;
        };
        init_adc_pins: init_adc_pinsgrp {                  /*!< Function assigned for the core: Cortex-M4[cm4] */
/*
 * TEXT BELOW IS USED AS SETTING FOR TOOLS *************************************
init_adc_pins:
- options: {callFromInitBoot: 'false', coreID: cm4}
- pin_list:
  - {pin_num: AD22, peripheral: ADC0, signal: adc_ch10a, pin_signal: PTA20}
  - {pin_num: AB16, peripheral: ADC1, signal: adc_ch5a, pin_signal: PTA8, identifier: ADC1_CH5A}
  - {pin_num: AC16, peripheral: ADC1, signal: adc_ch5b, pin_signal: PTA9, identifier: ADC1_CH5B}
  - {pin_num: AD16, peripheral: ADC1, signal: adc_ch6a, pin_signal: PTA10, identifier: ADC1_CH6A}
  - {pin_num: AD18, peripheral: ADC1, signal: adc_ch6b, pin_signal: PTA11, identifier: ADC1_CH6B}
 * BE CAREFUL MODIFYING THIS COMMENT - IT IS YAML SETTINGS FOR TOOLS ***********
 */
            fsl,pins = <
            >;
        };
        init_ewm_pins: init_ewm_pinsgrp {                  /*!< Function assigned for the core: Cortex-M4[cm4] */
/*
 * TEXT BELOW IS USED AS SETTING FOR TOOLS *************************************
init_ewm_pins:
- options: {callFromInitBoot: 'false', coreID: cm4}
- pin_list:
  - {pin_num: AC20, peripheral: EWM, signal: ewm_out_b, pin_signal: PTA22}
 * BE CAREFUL MODIFYING THIS COMMENT - IT IS YAML SETTINGS FOR TOOLS ***********
 */
            fsl,pins = <
            >;
        };
        init_sjc_pins: init_sjc_pinsgrp {                  /*!< Function assigned for the core: Cortex-M4[cm4] */
/*
 * TEXT BELOW IS USED AS SETTING FOR TOOLS *************************************
init_sjc_pins:
- options: {callFromInitBoot: 'false', coreID: cm4}
- pin_list:
  - {pin_num: AF21, peripheral: JTAG, signal: jtag_tms, pin_signal: PTA26, identifier: JTAG_TMS}
  - {pin_num: AF22, peripheral: JTAG, signal: jtag_tdo, pin_signal: PTA27}
  - {pin_num: AG22, peripheral: JTAG, signal: jtag_tdi, pin_signal: PTA28}
  - {pin_num: AD23, peripheral: JTAG, signal: jtag_tclk, pin_signal: PTA29, identifier: JTAG_TCLK}
  - {pin_num: AD24, peripheral: JTAG, signal: jtag_trst_b, pin_signal: PTA30}
 * BE CAREFUL MODIFYING THIS COMMENT - IT IS YAML SETTINGS FOR TOOLS ***********
 */
            fsl,pins = <
            >;
        };
        init_qspi_pins: init_qspi_pinsgrp {                /*!< Function assigned for the core: Cortex-M4[cm4] */
/*
 * TEXT BELOW IS USED AS SETTING FOR TOOLS *************************************
init_qspi_pins:
- options: {callFromInitBoot: 'false', coreID: cm4}
- pin_list:
  - {pin_num: AG6, peripheral: QSPIA, signal: 'qspia_ss_b, 0', pin_signal: PTB8}
  - {pin_num: AF8, peripheral: QSPIA, signal: qspia_sclk, pin_signal: PTB15}
  - {pin_num: AF9, peripheral: QSPIA, signal: 'qspia_data, 3', pin_signal: PTB16}
  - {pin_num: AF10, peripheral: QSPIA, signal: 'qspia_data, 2', pin_signal: PTB17}
  - {pin_num: AG10, peripheral: QSPIA, signal: 'qspia_data, 1', pin_signal: PTB18}
  - {pin_num: AD10, peripheral: QSPIA, signal: 'qspia_data, 0', pin_signal: PTB19}
 * BE CAREFUL MODIFYING THIS COMMENT - IT IS YAML SETTINGS FOR TOOLS ***********
 */
            fsl,pins = <
            >;
        };
        init_rtc_pins: init_rtc_pinsgrp {                  /*!< Function assigned for the core: Cortex-M4[cm4] */
/*
 * TEXT BELOW IS USED AS SETTING FOR TOOLS *************************************
init_rtc_pins:
- options: {callFromInitBoot: 'false', coreID: cm4}
- pin_list:
  - {pin_num: AG8, peripheral: RTC, signal: rtc_clkout, pin_signal: PTB14}
 * BE CAREFUL MODIFYING THIS COMMENT - IT IS YAML SETTINGS FOR TOOLS ***********
 */
            fsl,pins = <
            >;
        };
        init_usb_pins: init_usb_pinsgrp {                  /*!< Function assigned for the core: Cortex-M4[cm4] */
/*
 * TEXT BELOW IS USED AS SETTING FOR TOOLS *************************************
init_usb_pins:
- options: {callFromInitBoot: 'false', coreID: cm4}
- pin_list:
  - {pin_num: D13, peripheral: USB0, signal: usb0_id, pin_signal: PTC13}
  - {pin_num: G13, peripheral: USB1, signal: 'usb1_oc, 2', pin_signal: PTC16}
 * BE CAREFUL MODIFYING THIS COMMENT - IT IS YAML SETTINGS FOR TOOLS ***********
 */
            fsl,pins = <
                IMX7ULP_PAD_PTC13__USB0_ID                 0x00000B00
                IMX7ULP_PAD_PTC16__USB1_OC2                0x00000B00
            >;
        };
        init_sdhc_pins: init_sdhc_pinsgrp {                /*!< Function assigned for the core: Cortex-M4[cm4] */
/*
 * TEXT BELOW IS USED AS SETTING FOR TOOLS *************************************
init_sdhc_pins:
- options: {callFromInitBoot: 'false', coreID: cm4}
- pin_list:
  - {pin_num: A24, peripheral: SDHC0, signal: sdhc_reset_b, pin_signal: PTD0}
  - {pin_num: B24, peripheral: SDHC0, signal: sdhc_cmd, pin_signal: PTD1}
  - {pin_num: B23, peripheral: SDHC0, signal: sdhc_clk, pin_signal: PTD2, IBE: IBE_1_Enabled}
  - {pin_num: B22, peripheral: SDHC0, signal: 'sdhc_d, 7', pin_signal: PTD3}
  - {pin_num: A22, peripheral: SDHC0, signal: 'sdhc_d, 6', pin_signal: PTD4}
  - {pin_num: D21, peripheral: SDHC0, signal: 'sdhc_d, 5', pin_signal: PTD5}
  - {pin_num: D22, peripheral: SDHC0, signal: 'sdhc_d, 4', pin_signal: PTD6}
  - {pin_num: A20, peripheral: SDHC0, signal: 'sdhc_d, 3', pin_signal: PTD7}
  - {pin_num: B20, peripheral: SDHC0, signal: 'sdhc_d, 2', pin_signal: PTD8}
  - {pin_num: B19, peripheral: SDHC0, signal: 'sdhc_d, 1', pin_signal: PTD9}
  - {pin_num: B18, peripheral: SDHC0, signal: 'sdhc_d, 0', pin_signal: PTD10}
  - {pin_num: A18, peripheral: SDHC0, signal: sdhc_dqs, pin_signal: PTD11}
  - {pin_num: D12, peripheral: SDHC1, signal: 'sdhc_d, 1', pin_signal: PTE0}
  - {pin_num: A12, peripheral: SDHC1, signal: 'sdhc_d, 0', pin_signal: PTE1}
  - {pin_num: B12, peripheral: SDHC1, signal: sdhc_clk, pin_signal: PTE2, IBE: IBE_1_Enabled}
  - {pin_num: B11, peripheral: SDHC1, signal: sdhc_cmd, pin_signal: PTE3}
  - {pin_num: B10, peripheral: SDHC1, signal: 'sdhc_d, 3', pin_signal: PTE4}
  - {pin_num: A10, peripheral: SDHC1, signal: 'sdhc_d, 2', pin_signal: PTE5}
  - {pin_num: B6, peripheral: SDHC1, signal: sdhc_vs, pin_signal: PTE14}
 * BE CAREFUL MODIFYING THIS COMMENT - IT IS YAML SETTINGS FOR TOOLS ***********
 */
            fsl,pins = <
                IMX7ULP_PAD_PTD0__SDHC0_RESET_B            0x00000800
                IMX7ULP_PAD_PTD1__SDHC0_CMD                0x00000800
                IMX7ULP_PAD_PTD10__SDHC0_D0                0x00000800
                IMX7ULP_PAD_PTD11__SDHC0_DQS               0x00000800
                IMX7ULP_PAD_PTD2__SDHC0_CLK                0x00010800
                IMX7ULP_PAD_PTD3__SDHC0_D7                 0x00000800
                IMX7ULP_PAD_PTD4__SDHC0_D6                 0x00000800
                IMX7ULP_PAD_PTD5__SDHC0_D5                 0x00000800
                IMX7ULP_PAD_PTD6__SDHC0_D4                 0x00000800
                IMX7ULP_PAD_PTD7__SDHC0_D3                 0x00000800
                IMX7ULP_PAD_PTD8__SDHC0_D2                 0x00000800
                IMX7ULP_PAD_PTD9__SDHC0_D1                 0x00000800
                IMX7ULP_PAD_PTE0__SDHC1_D1                 0x00000800
                IMX7ULP_PAD_PTE1__SDHC1_D0                 0x00000800
                IMX7ULP_PAD_PTE14__SDHC1_VS                0x00000800
                IMX7ULP_PAD_PTE2__SDHC1_CLK                0x00010800
                IMX7ULP_PAD_PTE3__SDHC1_CMD                0x00000800
                IMX7ULP_PAD_PTE4__SDHC1_D3                 0x00000800
                IMX7ULP_PAD_PTE5__SDHC1_D2                 0x00000800
            >;
        };
        init_tpm_pins: init_tpm_pinsgrp {                  /*!< Function assigned for the core: Cortex-M4[cm4] */
/*
 * TEXT BELOW IS USED AS SETTING FOR TOOLS *************************************
init_tpm_pins:
- options: {callFromInitBoot: 'false', coreID: cm4}
- pin_list:
  - {pin_num: B3, peripheral: TPM4, signal: 'tpm_ch, 1', pin_signal: PTF2}
 * BE CAREFUL MODIFYING THIS COMMENT - IT IS YAML SETTINGS FOR TOOLS ***********
 */
            fsl,pins = <
                IMX7ULP_PAD_PTF2__TPM4_CH1                 0x00000600
            >;
        };
        init_lpspi_pins: init_lpspi_pinsgrp {              /*!< Function assigned for the core: Cortex-A7[ca7] */
/*
 * TEXT BELOW IS USED AS SETTING FOR TOOLS *************************************
init_lpspi_pins:
- options: {callFromInitBoot: 'true', coreID: ca7}
- pin_list:
  - {pin_num: H2, peripheral: LPSPI3, signal: lpspi_sout, pin_signal: PTF17}
  - {pin_num: J2, peripheral: LPSPI3, signal: lpspi_sck, pin_signal: PTF18}
  - {pin_num: K2, peripheral: LPSPI3, signal: 'lpspi_pcs, 0', pin_signal: PTF19}
  - {pin_num: H1, peripheral: LPSPI3, signal: lpspi_sin, pin_signal: PTF16}
 * BE CAREFUL MODIFYING THIS COMMENT - IT IS YAML SETTINGS FOR TOOLS ***********
 */
            fsl,pins = <
                IMX7ULP_PAD_PTF16__LPSPI3_SIN              0x00000300
                IMX7ULP_PAD_PTF17__LPSPI3_SOUT             0x00000300
                IMX7ULP_PAD_PTF18__LPSPI3_SCK              0x00000300
                IMX7ULP_PAD_PTF19__LPSPI3_PCS0             0x00000300
            >;
        };
    };
};

&iomuxc1_ddr {
    pinctrl-names = "default_iomuxc1_ddr";
    pinctrl-0 = <&init_gpio_pins>;


    imx7ulp-custom-board {
        init_gpio_pins: init_gpio_pinsgrp {                /*!< Function assigned for the core: Cortex-M4[cm4] */
/*
 * TEXT BELOW IS USED AS SETTING FOR TOOLS *************************************
init_gpio_pins:
- options: {callFromInitBoot: 'false', coreID: cm4}
- pin_list:
  - {pin_num: AG16, peripheral: PTA, signal: 'port, 12', pin_signal: PTA12, direction: OUTPUT, OBE: OBE_1_Enabled}
  - {pin_num: AF16, peripheral: PTA, signal: 'port, 13', pin_signal: PTA13, direction: INPUT, IBE: IBE_1_Enabled}
  - {pin_num: AF17, peripheral: PTA, signal: 'port, 14', pin_signal: PTA14, direction: OUTPUT, OBE: OBE_1_Enabled}
  - {pin_num: AF18, peripheral: PTA, signal: 'port, 15', pin_signal: PTA15, direction: OUTPUT, OBE: OBE_1_Enabled}
  - {pin_num: AB20, peripheral: PTA, signal: 'port, 21', pin_signal: PTA21, direction: OUTPUT, OBE: OBE_1_Enabled}
  - {pin_num: AD20, peripheral: PTA, signal: 'port, 23', pin_signal: PTA23, direction: INPUT, IBE: IBE_1_Enabled}
  - {pin_num: AF20, peripheral: PTA, signal: 'port, 24', pin_signal: PTA24, direction: OUTPUT, OBE: OBE_1_Enabled}
  - {pin_num: AG20, peripheral: PTA, signal: 'port, 25', pin_signal: PTA25, direction: OUTPUT, OBE: OBE_1_Enabled}
  - {pin_num: AF14, peripheral: PTA, signal: 'port, 3', pin_signal: PTA3, direction: OUTPUT, OBE: OBE_1_Enabled}
  - {pin_num: AF24, peripheral: PTA, signal: 'port, 31', pin_signal: PTA31, direction: INPUT, IBE: IBE_1_Enabled}
  - {pin_num: AF5, peripheral: PTB, signal: 'port, 6', pin_signal: PTB6, direction: OUTPUT, OBE: OBE_1_Enabled}
  - {pin_num: AF6, peripheral: PTB, signal: 'port, 7', pin_signal: PTB7, direction: INPUT, IBE: IBE_1_Enabled}
  - {pin_num: AD7, peripheral: PTB, signal: 'port, 9', pin_signal: PTB9, direction: INPUT, IBE: IBE_1_Enabled}
  - {pin_num: AB7, peripheral: PTB, signal: 'port, 11', pin_signal: PTB11, direction: INPUT, IBE: IBE_1_Enabled}
  - {pin_num: D18, peripheral: PTC, signal: 'port, 0', pin_signal: PTC0, direction: OUTPUT, OBE: OBE_1_Enabled}
  - {pin_num: B15, peripheral: PTC, signal: 'port, 10', pin_signal: PTC10, direction: INPUT, IBE: IBE_1_Enabled, PE: PE_1_pull_enabled, PS: PS_1_pull_up}
  - {pin_num: B14, peripheral: PTC, signal: 'port, 11', pin_signal: PTC11, direction: INPUT, IBE: IBE_1_Enabled}
  - {pin_num: A14, peripheral: PTC, signal: 'port, 12', pin_signal: PTC12, direction: INPUT, IBE: IBE_1_Enabled}
  - {pin_num: E13, peripheral: PTC, signal: 'port, 14', pin_signal: PTC14, direction: OUTPUT, OBE: OBE_1_Enabled}
  - {pin_num: F13, peripheral: PTC, signal: 'port, 15', pin_signal: PTC15, direction: OUTPUT, OBE: OBE_1_Enabled}
  - {pin_num: G12, peripheral: PTC, signal: 'port, 17', pin_signal: PTC17, direction: OUTPUT, OBE: OBE_1_Enabled}
  - {pin_num: F12, peripheral: PTC, signal: 'port, 18', pin_signal: PTC18, direction: INPUT, IBE: IBE_1_Enabled, PE: PE_1_pull_enabled, PS: PS_1_pull_up}
  - {pin_num: E12, peripheral: PTC, signal: 'port, 19', pin_signal: PTC19, direction: OUTPUT, OBE: OBE_1_Enabled, PE: PE_1_pull_enabled, PS: PS_1_pull_up}
  - {pin_num: B8, peripheral: PTE, signal: 'port, 12', pin_signal: PTE12, direction: OUTPUT, OBE: OBE_1_Enabled}
  - {pin_num: D2, peripheral: PTF, signal: 'port, 0', pin_signal: PTF0, direction: INPUT, IBE: IBE_1_Enabled}
  - {pin_num: B2, peripheral: PTF, signal: 'port, 1', pin_signal: PTF1, direction: OUTPUT, OBE: OBE_1_Enabled}
  - {pin_num: G5, peripheral: PTF, signal: 'port, 10', pin_signal: PTF10, direction: OUTPUT, OBE: OBE_1_Enabled}
  - {pin_num: G6, peripheral: PTF, signal: 'port, 11', pin_signal: PTF11, direction: OUTPUT, OBE: OBE_1_Enabled}
 * BE CAREFUL MODIFYING THIS COMMENT - IT IS YAML SETTINGS FOR TOOLS ***********
 */
            fsl,pins = <
            >;
        };
        init_i2s_pins: init_i2s_pinsgrp {                  /*!< Function assigned for the core: Cortex-M4[cm4] */
/*
 * TEXT BELOW IS USED AS SETTING FOR TOOLS *************************************
init_i2s_pins:
- options: {callFromInitBoot: 'false', coreID: cm4}
- pin_list:
  - {pin_num: AG14, peripheral: I2S0, signal: 'i2s_rxd, 0', pin_signal: PTA2, DSE: DSE_1_Hi_Drive}
  - {pin_num: AD15, peripheral: I2S0, signal: i2s_mclk, pin_signal: PTA4, DSE: DSE_1_Hi_Drive}
  - {pin_num: AC15, peripheral: I2S0, signal: i2s_tx_bclk, pin_signal: PTA5, DSE: DSE_1_Hi_Drive}
  - {pin_num: AB15, peripheral: I2S0, signal: i2s_tx_fs, pin_signal: PTA6, DSE: DSE_1_Hi_Drive}
  - {pin_num: AD14, peripheral: I2S0, signal: 'i2s_txd, 0', pin_signal: PTA7, DSE: DSE_1_Hi_Drive}
  - {pin_num: AF2, peripheral: I2S1, signal: i2s_tx_bclk, pin_signal: PTB1, DSE: DSE_1_Hi_Drive}
  - {pin_num: AE3, peripheral: I2S1, signal: i2s_tx_fs, pin_signal: PTB2, DSE: DSE_1_Hi_Drive}
  - {pin_num: AE4, peripheral: I2S1, signal: 'i2s_txd, 0', pin_signal: PTB3, DSE: DSE_1_Hi_Drive}
  - {pin_num: AC7, peripheral: I2S1, signal: 'i2s_rxd, 0', pin_signal: PTB10, DSE: DSE_1_Hi_Drive}
 * BE CAREFUL MODIFYING THIS COMMENT - IT IS YAML SETTINGS FOR TOOLS ***********
 */
            fsl,pins = <
            >;
        };
        init_uart_pins: init_uart_pinsgrp {                /*!< Function assigned for the core: Cortex-M4[cm4] */
/*
 * TEXT BELOW IS USED AS SETTING FOR TOOLS *************************************
init_uart_pins:
- options: {callFromInitBoot: 'false', coreID: cm4}
- pin_list:
  - {pin_num: AB16, peripheral: LPUART2, signal: lpuart_cts_b, pin_signal: PTA8, identifier: UART2_CTS, PE: PE_1_pull_enabled, PS: PS_1_pull_up}
  - {pin_num: AC16, peripheral: LPUART2, signal: lpuart_rts_b, pin_signal: PTA9, identifier: UART2_RTS, PE: PE_1_pull_enabled, PS: PS_1_pull_up}
  - {pin_num: AD16, peripheral: LPUART2, signal: lpuart_tx, pin_signal: PTA10, identifier: UART2_TX, PE: PE_1_pull_enabled, PS: PS_1_pull_up}
  - {pin_num: AD18, peripheral: LPUART2, signal: lpuart_rx, pin_signal: PTA11, identifier: UART2_RX, PE: PE_1_pull_enabled, PS: PS_1_pull_up}
  - {pin_num: AC19, peripheral: LPUART0, signal: lpuart_tx, pin_signal: PTA18, PE: PE_1_pull_enabled, PS: PS_1_pull_up}
  - {pin_num: AB19, peripheral: LPUART0, signal: lpuart_rx, pin_signal: PTA19, PE: PE_1_pull_enabled, PS: PS_1_pull_up}
  - {pin_num: F17, peripheral: LPUART4, signal: lpuart_tx, pin_signal: PTC2, PE: PE_1_pull_enabled, PS: PS_1_pull_up}
  - {pin_num: G17, peripheral: LPUART4, signal: lpuart_rx, pin_signal: PTC3, PE: PE_1_pull_enabled, PS: PS_1_pull_up}
  - {pin_num: F9, peripheral: LPUART6, signal: lpuart_cts_b, pin_signal: PTE8, PE: PE_1_pull_enabled, PS: PS_1_pull_up}
  - {pin_num: G9, peripheral: LPUART6, signal: lpuart_rts_b, pin_signal: PTE9, PE: PE_1_pull_enabled, PS: PS_1_pull_up}
  - {pin_num: D8, peripheral: LPUART6, signal: lpuart_tx, pin_signal: PTE10, PE: PE_1_pull_enabled, PS: PS_1_pull_up}
  - {pin_num: A8, peripheral: LPUART6, signal: lpuart_rx, pin_signal: PTE11, PE: PE_1_pull_enabled, PS: PS_1_pull_up}
 * BE CAREFUL MODIFYING THIS COMMENT - IT IS YAML SETTINGS FOR TOOLS ***********
 */
            fsl,pins = <
            >;
        };
        init_i2c_pins: init_i2c_pinsgrp {                  /*!< Function assigned for the core: Cortex-M4[cm4] */
/*
 * TEXT BELOW IS USED AS SETTING FOR TOOLS *************************************
init_i2c_pins:
- options: {callFromInitBoot: 'false', coreID: cm4}
- pin_list:
  - {pin_num: AG18, peripheral: LPI2C0, signal: lpi2c_scl, pin_signal: PTA16, ODE: ODE_1_Open_drain}
  - {pin_num: AD19, peripheral: LPI2C0, signal: lpi2c_sda, pin_signal: PTA17, ODE: ODE_1_Open_drain}
  - {pin_num: AC8, peripheral: LPI2C3, signal: lpi2c_scl, pin_signal: PTB12, ODE: ODE_1_Open_drain}
  - {pin_num: AD8, peripheral: LPI2C3, signal: lpi2c_sda, pin_signal: PTB13, ODE: ODE_1_Open_drain}
  - {pin_num: F16, peripheral: LPI2C5, signal: lpi2c_scl, pin_signal: PTC4, ODE: ODE_1_Open_drain}
  - {pin_num: D17, peripheral: LPI2C5, signal: lpi2c_sda, pin_signal: PTC5, ODE: ODE_1_Open_drain}
  - {pin_num: H7, peripheral: LPI2C7, signal: lpi2c_scl, pin_signal: PTF12, ODE: ODE_1_Open_drain}
  - {pin_num: H6, peripheral: LPI2C7, signal: lpi2c_sda, pin_signal: PTF13, ODE: ODE_1_Open_drain}
 * BE CAREFUL MODIFYING THIS COMMENT - IT IS YAML SETTINGS FOR TOOLS ***********
 */
            fsl,pins = <
            >;
        };
        init_adc_pins: init_adc_pinsgrp {                  /*!< Function assigned for the core: Cortex-M4[cm4] */
/*
 * TEXT BELOW IS USED AS SETTING FOR TOOLS *************************************
init_adc_pins:
- options: {callFromInitBoot: 'false', coreID: cm4}
- pin_list:
  - {pin_num: AD22, peripheral: ADC0, signal: adc_ch10a, pin_signal: PTA20}
  - {pin_num: AB16, peripheral: ADC1, signal: adc_ch5a, pin_signal: PTA8, identifier: ADC1_CH5A}
  - {pin_num: AC16, peripheral: ADC1, signal: adc_ch5b, pin_signal: PTA9, identifier: ADC1_CH5B}
  - {pin_num: AD16, peripheral: ADC1, signal: adc_ch6a, pin_signal: PTA10, identifier: ADC1_CH6A}
  - {pin_num: AD18, peripheral: ADC1, signal: adc_ch6b, pin_signal: PTA11, identifier: ADC1_CH6B}
 * BE CAREFUL MODIFYING THIS COMMENT - IT IS YAML SETTINGS FOR TOOLS ***********
 */
            fsl,pins = <
            >;
        };
        init_ewm_pins: init_ewm_pinsgrp {                  /*!< Function assigned for the core: Cortex-M4[cm4] */
/*
 * TEXT BELOW IS USED AS SETTING FOR TOOLS *************************************
init_ewm_pins:
- options: {callFromInitBoot: 'false', coreID: cm4}
- pin_list:
  - {pin_num: AC20, peripheral: EWM, signal: ewm_out_b, pin_signal: PTA22}
 * BE CAREFUL MODIFYING THIS COMMENT - IT IS YAML SETTINGS FOR TOOLS ***********
 */
            fsl,pins = <
            >;
        };
        init_sjc_pins: init_sjc_pinsgrp {                  /*!< Function assigned for the core: Cortex-M4[cm4] */
/*
 * TEXT BELOW IS USED AS SETTING FOR TOOLS *************************************
init_sjc_pins:
- options: {callFromInitBoot: 'false', coreID: cm4}
- pin_list:
  - {pin_num: AF21, peripheral: JTAG, signal: jtag_tms, pin_signal: PTA26, identifier: JTAG_TMS}
  - {pin_num: AF22, peripheral: JTAG, signal: jtag_tdo, pin_signal: PTA27}
  - {pin_num: AG22, peripheral: JTAG, signal: jtag_tdi, pin_signal: PTA28}
  - {pin_num: AD23, peripheral: JTAG, signal: jtag_tclk, pin_signal: PTA29, identifier: JTAG_TCLK}
  - {pin_num: AD24, peripheral: JTAG, signal: jtag_trst_b, pin_signal: PTA30}
 * BE CAREFUL MODIFYING THIS COMMENT - IT IS YAML SETTINGS FOR TOOLS ***********
 */
            fsl,pins = <
            >;
        };
        init_qspi_pins: init_qspi_pinsgrp {                /*!< Function assigned for the core: Cortex-M4[cm4] */
/*
 * TEXT BELOW IS USED AS SETTING FOR TOOLS *************************************
init_qspi_pins:
- options: {callFromInitBoot: 'false', coreID: cm4}
- pin_list:
  - {pin_num: AG6, peripheral: QSPIA, signal: 'qspia_ss_b, 0', pin_signal: PTB8}
  - {pin_num: AF8, peripheral: QSPIA, signal: qspia_sclk, pin_signal: PTB15}
  - {pin_num: AF9, peripheral: QSPIA, signal: 'qspia_data, 3', pin_signal: PTB16}
  - {pin_num: AF10, peripheral: QSPIA, signal: 'qspia_data, 2', pin_signal: PTB17}
  - {pin_num: AG10, peripheral: QSPIA, signal: 'qspia_data, 1', pin_signal: PTB18}
  - {pin_num: AD10, peripheral: QSPIA, signal: 'qspia_data, 0', pin_signal: PTB19}
 * BE CAREFUL MODIFYING THIS COMMENT - IT IS YAML SETTINGS FOR TOOLS ***********
 */
            fsl,pins = <
            >;
        };
        init_rtc_pins: init_rtc_pinsgrp {                  /*!< Function assigned for the core: Cortex-M4[cm4] */
/*
 * TEXT BELOW IS USED AS SETTING FOR TOOLS *************************************
init_rtc_pins:
- options: {callFromInitBoot: 'false', coreID: cm4}
- pin_list:
  - {pin_num: AG8, peripheral: RTC, signal: rtc_clkout, pin_signal: PTB14}
 * BE CAREFUL MODIFYING THIS COMMENT - IT IS YAML SETTINGS FOR TOOLS ***********
 */
            fsl,pins = <
            >;
        };
        init_usb_pins: init_usb_pinsgrp {                  /*!< Function assigned for the core: Cortex-M4[cm4] */
/*
 * TEXT BELOW IS USED AS SETTING FOR TOOLS *************************************
init_usb_pins:
- options: {callFromInitBoot: 'false', coreID: cm4}
- pin_list:
  - {pin_num: D13, peripheral: USB0, signal: usb0_id, pin_signal: PTC13}
  - {pin_num: G13, peripheral: USB1, signal: 'usb1_oc, 2', pin_signal: PTC16}
 * BE CAREFUL MODIFYING THIS COMMENT - IT IS YAML SETTINGS FOR TOOLS ***********
 */
            fsl,pins = <
            >;
        };
        init_sdhc_pins: init_sdhc_pinsgrp {                /*!< Function assigned for the core: Cortex-M4[cm4] */
/*
 * TEXT BELOW IS USED AS SETTING FOR TOOLS *************************************
init_sdhc_pins:
- options: {callFromInitBoot: 'false', coreID: cm4}
- pin_list:
  - {pin_num: A24, peripheral: SDHC0, signal: sdhc_reset_b, pin_signal: PTD0}
  - {pin_num: B24, peripheral: SDHC0, signal: sdhc_cmd, pin_signal: PTD1}
  - {pin_num: B23, peripheral: SDHC0, signal: sdhc_clk, pin_signal: PTD2, IBE: IBE_1_Enabled}
  - {pin_num: B22, peripheral: SDHC0, signal: 'sdhc_d, 7', pin_signal: PTD3}
  - {pin_num: A22, peripheral: SDHC0, signal: 'sdhc_d, 6', pin_signal: PTD4}
  - {pin_num: D21, peripheral: SDHC0, signal: 'sdhc_d, 5', pin_signal: PTD5}
  - {pin_num: D22, peripheral: SDHC0, signal: 'sdhc_d, 4', pin_signal: PTD6}
  - {pin_num: A20, peripheral: SDHC0, signal: 'sdhc_d, 3', pin_signal: PTD7}
  - {pin_num: B20, peripheral: SDHC0, signal: 'sdhc_d, 2', pin_signal: PTD8}
  - {pin_num: B19, peripheral: SDHC0, signal: 'sdhc_d, 1', pin_signal: PTD9}
  - {pin_num: B18, peripheral: SDHC0, signal: 'sdhc_d, 0', pin_signal: PTD10}
  - {pin_num: A18, peripheral: SDHC0, signal: sdhc_dqs, pin_signal: PTD11}
  - {pin_num: D12, peripheral: SDHC1, signal: 'sdhc_d, 1', pin_signal: PTE0}
  - {pin_num: A12, peripheral: SDHC1, signal: 'sdhc_d, 0', pin_signal: PTE1}
  - {pin_num: B12, peripheral: SDHC1, signal: sdhc_clk, pin_signal: PTE2, IBE: IBE_1_Enabled}
  - {pin_num: B11, peripheral: SDHC1, signal: sdhc_cmd, pin_signal: PTE3}
  - {pin_num: B10, peripheral: SDHC1, signal: 'sdhc_d, 3', pin_signal: PTE4}
  - {pin_num: A10, peripheral: SDHC1, signal: 'sdhc_d, 2', pin_signal: PTE5}
  - {pin_num: B6, peripheral: SDHC1, signal: sdhc_vs, pin_signal: PTE14}
 * BE CAREFUL MODIFYING THIS COMMENT - IT IS YAML SETTINGS FOR TOOLS ***********
 */
            fsl,pins = <
            >;
        };
        init_tpm_pins: init_tpm_pinsgrp {                  /*!< Function assigned for the core: Cortex-M4[cm4] */
/*
 * TEXT BELOW IS USED AS SETTING FOR TOOLS *************************************
init_tpm_pins:
- options: {callFromInitBoot: 'false', coreID: cm4}
- pin_list:
  - {pin_num: B3, peripheral: TPM4, signal: 'tpm_ch, 1', pin_signal: PTF2}
 * BE CAREFUL MODIFYING THIS COMMENT - IT IS YAML SETTINGS FOR TOOLS ***********
 */
            fsl,pins = <
            >;
        };
        init_lpspi_pins: init_lpspi_pinsgrp {              /*!< Function assigned for the core: Cortex-A7[ca7] */
/*
 * TEXT BELOW IS USED AS SETTING FOR TOOLS *************************************
init_lpspi_pins:
- options: {callFromInitBoot: 'true', coreID: ca7}
- pin_list:
  - {pin_num: H2, peripheral: LPSPI3, signal: lpspi_sout, pin_signal: PTF17}
  - {pin_num: J2, peripheral: LPSPI3, signal: lpspi_sck, pin_signal: PTF18}
  - {pin_num: K2, peripheral: LPSPI3, signal: 'lpspi_pcs, 0', pin_signal: PTF19}
  - {pin_num: H1, peripheral: LPSPI3, signal: lpspi_sin, pin_signal: PTF16}
 * BE CAREFUL MODIFYING THIS COMMENT - IT IS YAML SETTINGS FOR TOOLS ***********
 */
            fsl,pins = <
            >;
        };
    };
};

/***********************************************************************************************************************
 * EOF
 **********************************************************************************************************************/
